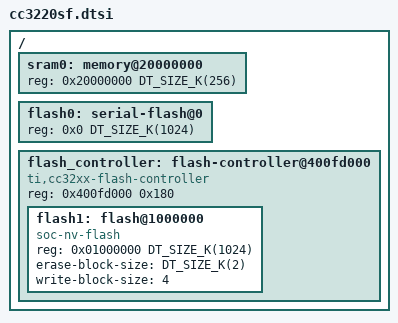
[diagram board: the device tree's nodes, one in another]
/*
 * Copyright (c) 2018 Linaro Limited
 *
 * SPDX-License-Identifier: Apache-2.0
 */

#include <mem.h>
#include <ti/cc32xx.dtsi>

/ {
	sram0: memory@20000000 {
		reg = <0x20000000 DT_SIZE_K(256)>;
	};

	flash0: serial-flash@0 {
		reg = <0x0 DT_SIZE_K(1024)>;
	};

	flash_controller: flash-controller@400fd000 {
		compatible = "ti,cc32xx-flash-controller";
		reg = <0x400fd000 0x180>;

		#address-cells = <1>;
		#size-cells = <1>;

		flash1: flash@1000000 {
			compatible = "soc-nv-flash";
			reg = <0x01000000 DT_SIZE_K(1024)>;
			erase-block-size = <DT_SIZE_K(2)>;
			write-block-size = <4>;
		};
	};
};
